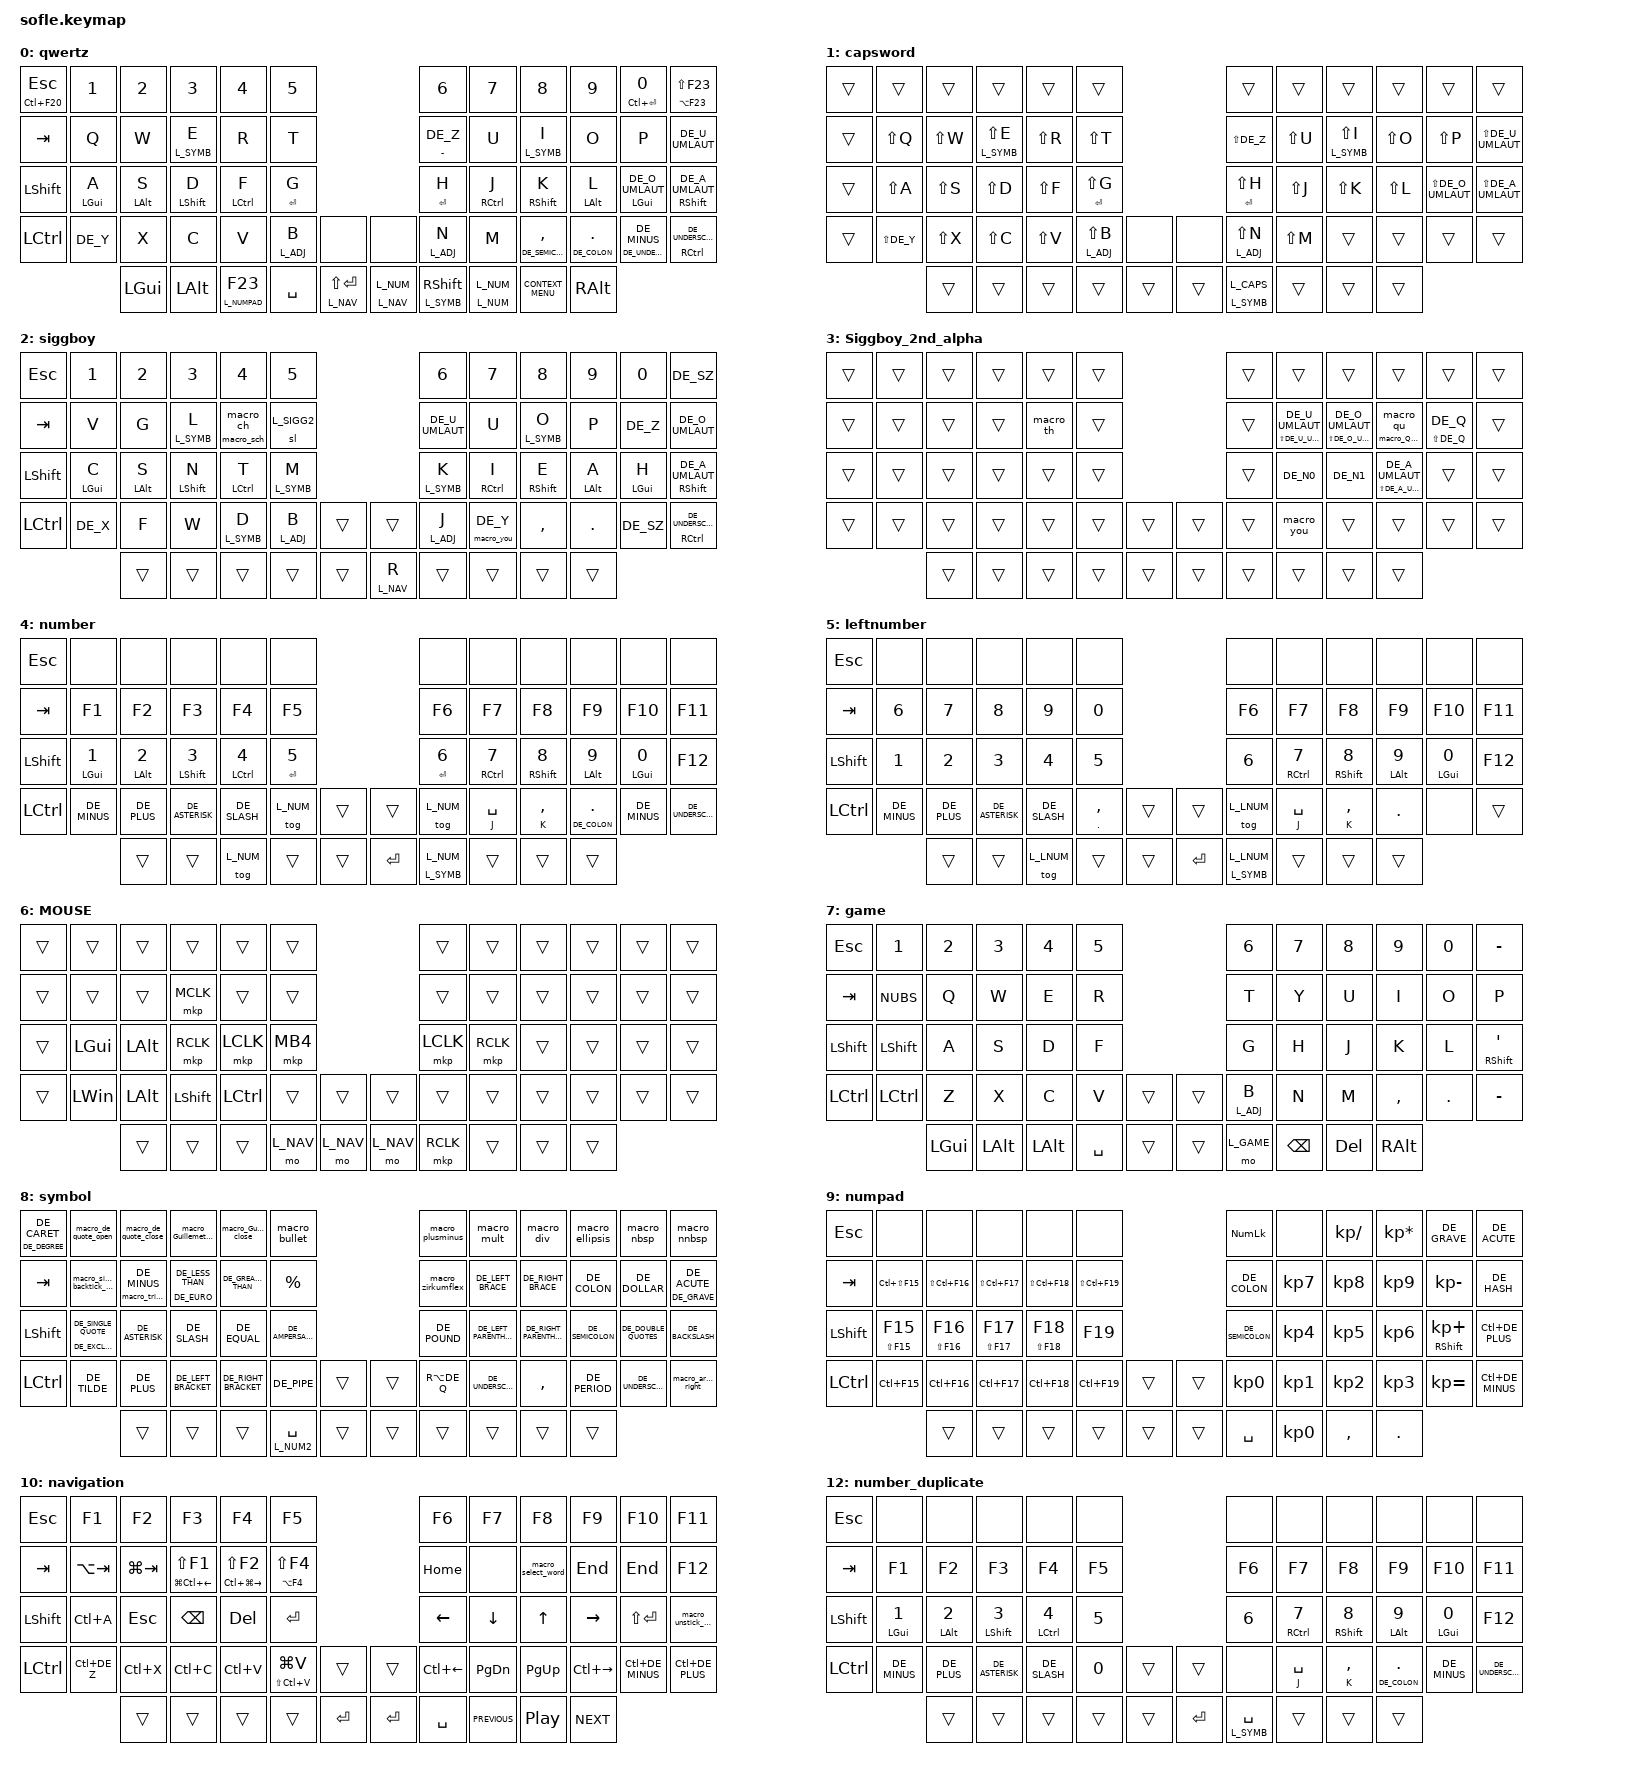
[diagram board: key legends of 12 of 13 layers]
/*
 * Copyright (c) 2020 The ZMK Contributors
 *
 * SPDX-License-Identifier: MIT
 */

#include <behaviors/anti_idle_mode.dtsi>
#include <dt-bindings/anti_idle_mode.h>
#include <behaviors.dtsi>
#include <dt-bindings/zmk/bt.h>
#include <dt-bindings/zmk/keys.h>
#include <dt-bindings/zmk/outputs.h>
#include <dt-bindings/zmk/pointing.h>

#ifndef KEYMAP_DRAWER

#include "keys_de.h"

#endif

// #include <behaviors/mouse.dtsi>
/* Global settings */

#define QUICK_TAP_MS 175

#include "layers.h"

&sl { ignore-modifiers; };

&left_encoder { steps = <60>; };

&right_encoder { steps = <60>; };

/ {
    // Activate ADJUST layer by pressing raise and lower

    conditional_layers { compatible = "zmk,conditional-layers"; };

    combos {
        compatible = "zmk,combos";

        combo_F24_minimize_Window {
            bindings = <&kp LC(F24)>;
            key-positions = <0 1>;
            layers = <LAYERS_MOST>;
            timeout-ms = <50>;
            require-prior-idle-ms = <90>;
        };

        combo_CTRL_Z {
            bindings = <&kp LC(DE_Z)>;
            key-positions = <>;
            layers = <LAYERS_MOST>;
            timeout-ms = <30>;
            require-prior-idle-ms = <100>;
        };

        combo_copy_cut {
            bindings = <&mt LC(X) LC(C)>;
            key-positions = <>;
            layers = <LAYERS_MOST>;
            timeout-ms = <30>;
            require-prior-idle-ms = <100>;
        };

        combo_CTRL_V {
            bindings = <&kp LC(V)>;
            key-positions = <>;
            layers = <LAYERS_MOST>;
            timeout-ms = <22>;
            require-prior-idle-ms = <100>;
        };

        combo_win_paste {
            bindings = <&mod_taptap_150 LS(LC(V)) LG(V)>;
            key-positions = <>;
            layers = <LAYERS_MOST>;
            timeout-ms = <30>;
            require-prior-idle-ms = <100>;
        };

        combo_CTRL_Y {
            bindings = <&kp LC(DE_Y)>;
            key-positions = <>;
            layers = <LAYERS_MOST>;
            timeout-ms = <30>;
            require-prior-idle-ms = <100>;
        };

        combo_CTRL_Backspace {
            bindings = <&kp LC(BACKSPACE)>;
            key-positions = <19 20>;
            layers = <LAYERS_MOST>;
            timeout-ms = <30>;
            require-prior-idle-ms = <100>;
        };

        combo_CTRL_Delete {
            bindings = <&kp LC(DELETE)>;
            key-positions = <20 21>;
            layers = <LAYERS_MOST>;
            timeout-ms = <25>;
            require-prior-idle-ms = <100>;
        };

        combo_Printscreen1 {
            bindings = <&kp PRINTSCREEN>;
            key-positions = <10 11>;
            layers = <LAYERS_MOST>;
            timeout-ms = <30>;
            require-prior-idle-ms = <100>;
        };

        combo_Guillemets_open {
            bindings = <&macro_Guillemets_open>;
            key-positions = <1 2>;
            layers = <LAYERS_WRITE>;
            timeout-ms = <40>;
            require-prior-idle-ms = <100>;
        };

        combo_Guillemets_close {
            bindings = <&macro_Guillemets_close>;
            key-positions = <2 3>;
            layers = <LAYERS_WRITE>;
            timeout-ms = <40>;
            require-prior-idle-ms = <100>;
        };

        combo_capsword {
            bindings = <&caps_word_al L_CAPS>;
            key-positions = <25 34>;
            layers = <LAYERS_WRITE>;
            timeout-ms = <65>;
            require-prior-idle-ms = <150>;
        };

        combo_en_dash2 {
            bindings = <&macro_en_dash>;
            key-positions = <48 47>;
            layers = <LAYERS_WRITE>;
            timeout-ms = <50>;
            require-prior-idle-ms = <100>;
        };

        combo_question {
            bindings = <&kp DE_QUESTION>;
            key-positions = <46 47>;
            layers = <LAYERS_MOST>;
            timeout-ms = <50>;
            require-prior-idle-ms = <75>;
        };

        combo_exclamation {
            bindings = <&kp EXCLAMATION>;
            key-positions = <46 45>;
            layers = <LAYERS_MOST>;
            timeout-ms = <45>;
            require-prior-idle-ms = <100>;
        };

        combo_Backspace {
            bindings = <&kp BACKSPACE>;
            key-positions = <31 32>;
            layers = <LAYERS_MOST>;
            timeout-ms = <30>;
            require-prior-idle-ms = <70>;
        };

        combo_listary_new {
            bindings = <&kp F22>;
            key-positions = <28 29>;
            layers = <LAYERS_MOST>;
            timeout-ms = <30>;
            require-prior-idle-ms = <100>;
        };

        combo_new_window {
            bindings = <&kp LC(N)>;
            key-positions = <16 17>;
            timeout-ms = <35>;
            require-prior-idle-ms = <300>;
            layers = <LAYERS_MOST>;
        };

        combo_em_dash2 {
            bindings = <&macro_em_dash>;
            key-positions = <47 48 46>;
            timeout-ms = <50>;
            require-prior-idle-ms = <100>;
            layers = <LAYERS_WRITE>;
        };

        combo_new_tab {
            bindings = <&kp LC(T)>;
            key-positions = <16 15>;
            timeout-ms = <30>;
            require-prior-idle-ms = <300>;
            layers = <LAYERS_MOST>;
        };

        combo_Delete {
            bindings = <&kp DELETE>;
            key-positions = <32 33>;
            timeout-ms = <25>;
            require-prior-idle-ms = <150>;
            layers = <LAYERS_MOST>;
        };

        combo_arrowa_right {
            bindings = <&macro_arrow_right>;
            key-positions = <48 49>;
            timeout-ms = <50>;
            require-prior-idle-ms = <100>;
            layers = <LAYERS_WRITE>;
        };

        combo_Paste_withouta_formatting {
            bindings = <&kp LC(LS(V))>;
            key-positions = <>;
            timeout-ms = <30>;
            require-prior-idle-ms = <100>;
            layers = <LAYERS_MOST>;
        };

        combo_change_audiodevice {
            bindings = <&kp LA(LS(LC(F14)))>;
            key-positions = <5 6>;
            timeout-ms = <40>;
            layers = <LAYERS_MOST>;
        };

        combo_Printscreen2 {
            bindings = <&kp PRINTSCREEN>;
            key-positions = <4 5>;
            timeout-ms = <40>;
            require-prior-idle-ms = <100>;
            layers = <LAYERS_MOST>;
        };

        combo_CTRL_Z_2 {
            bindings = <&kp LC(DE_Z)>;
            key-positions = <18 19>;
            timeout-ms = <30>;
            require-prior-idle-ms = <100>;
            layers = <LAYERS_MOST>;
        };

        combo_Menuekey {
            bindings = <&kp K_CONTEXT_MENU>;
            key-positions = <50 51>;
            timeout-ms = <30>;
            require-prior-idle-ms = <100>;
            layers = <LAYERS_MOST>;
        };

        combo_p {
            bindings = <&macro_p>;
            key-positions = <41 40>;
            layers = <L_ADJ>;
        };

        combo_escape {
            bindings = <&kp ESCAPE>;
            key-positions = <27 32>;
            timeout-ms = <55>;
            require-prior-idle-ms = <120>;
            layers = <LAYERS_ALL>;
        };

        combo_F24_minimize_Window_2 {
            bindings = <&kp LC(F24)>;
            key-positions = <15 14>;
            timeout-ms = <22>;
            require-prior-idle-ms = <150>;
            layers = <LAYERS_MOST>;
        };

        combo_number_layer_left {
            bindings = <&tog L_LNUM>;
            key-positions = <38 39>;
            layers = <LAYERS_WRITE>;
            timeout-ms = <50>;
            require-prior-idle-ms = <80>;
        };

        combo_exit_left_numberlayer {
            bindings = <&tog L_LNUM>;
            key-positions = <38 39>;
            layers = <L_LNUM>;
        };

        combo_escape2 {
            bindings = <&kp ESCAPE>;
            key-positions = <26 27>;
            timeout-ms = <30>;
            require-prior-idle-ms = <70>;
            layers = <LAYERS_ALL>;
        };

        combo_Shift_Enter {
            bindings = <&mod_taptap_150 LC(ENTER) LS(ENTER)>;
            key-positions = <31 30>;
            timeout-ms = <30>;
            require-prior-idle-ms = <70>;
            layers = <LAYERS_MOST>;
        };

        combo_raycast {
            bindings = <&kp LA(SPACE)>;
            key-positions = <28 27>;
            timeout-ms = <30>;
            require-prior-idle-ms = <70>;
            layers = <LAYERS_MOST>;
        };

        combo_f24_universal_key_2 {
            bindings = <&mod_taptap_150 LS(F24) F24>;
            key-positions = <28 31>;
            timeout-ms = <30>;
            require-prior-idle-ms = <70>;
            layers = <LAYERS_MOST>;
        };

        combo_+f24_universal_key_3 {
            bindings = <&kp LS(F24)>;
            key-positions = <28 30>;
            timeout-ms = <30>;
            require-prior-idle-ms = <70>;
            layers = <LAYERS_MOST>;
        };
    };

    macros {
        macro_Guillemets_open: macro_Guillemets_open {
            compatible = "zmk,behavior-macro";
            #binding-cells = <0>;
            bindings =
                <&macro_press>,
                <&kp LEFT_ALT>,
                <&macro_tap>,
                <&kp KP_N0 &kp KP_N1 &kp KP_N7 &kp KP_N1>,
                <&macro_release>,
                <&kp LEFT_ALT>;

            label = "MACRO_GUILLEMETS_OPEN";
            wait-ms = <7>;
            tap-ms = <10>;
        };

        macro_Guillemets_close: macro_Guillemets_close {
            compatible = "zmk,behavior-macro";
            #binding-cells = <0>;
            bindings =
                <&macro_press>,
                <&kp LEFT_ALT>,
                <&macro_tap>,
                <&kp KP_N0 &kp KP_N1 &kp KP_N8 &kp KP_N7>,
                <&macro_release>,
                <&kp LEFT_ALT>;

            label = "MACRO_GUILLEMETS_CLOSE";
            wait-ms = <7>;
            tap-ms = <10>;
        };

        // 1: Deutsch Anführungszeichen unten „ (Alt+0132)

        macro_de_quote_open: macro_de_quote_open {
            compatible = "zmk,behavior-macro";
            #binding-cells = <0>;
            wait-ms = <7>;
            tap-ms = <10>;
            bindings =
                <&macro_press>,
                <&kp LALT>,
                <&macro_tap>,
                <&kp KP_N0 &kp KP_N1 &kp KP_N3 &kp KP_N2>,
                <&macro_release>,
                <&kp LALT>;
        };

        // 2: Deutsch Anführungszeichen oben “ (Alt+0147)

        macro_de_quote_close: macro_de_quote_close {
            compatible = "zmk,behavior-macro";
            #binding-cells = <0>;
            wait-ms = <7>;
            tap-ms = <10>;
            bindings =
                <&macro_press>,
                <&kp LALT>,
                <&macro_tap>,
                <&kp KP_N0 &kp KP_N1 &kp KP_N4 &kp KP_N7>,
                <&macro_release>,
                <&kp LALT>;
        };

        // 3: Französische Guillemets open « (Alt+0171)
        // 4: Französische Guillemets close » (Alt+0187)
        // 5: Bullet Point • (Alt+0149)

        macro_bullet: macro_bullet {
            compatible = "zmk,behavior-macro";
            #binding-cells = <0>;
            wait-ms = <7>;
            tap-ms = <10>;
            bindings =
                <&macro_press>,
                <&kp LALT>,
                <&macro_tap>,
                <&kp KP_N0 &kp KP_N1 &kp KP_N4 &kp KP_N9>,
                <&macro_release>,
                <&kp LALT>;
        };

        // 6: Ellipse … (Alt+0133)

        macro_ellipsis: macro_ellipsis {
            compatible = "zmk,behavior-macro";
            #binding-cells = <0>;
            wait-ms = <7>;
            tap-ms = <10>;
            bindings =
                <&macro_press>,
                <&kp LALT>,
                <&macro_tap>,
                <&kp KP_N0 &kp KP_N1 &kp KP_N3 &kp KP_N3>,
                <&macro_release>,
                <&kp LALT>;
        };

        // 7: Plus-Minus ± (Alt+0177)

        macro_plusminus: macro_plusminus {
            compatible = "zmk,behavior-macro";
            #binding-cells = <0>;
            wait-ms = <7>;
            tap-ms = <10>;
            bindings =
                <&macro_press>,
                <&kp LALT>,
                <&macro_tap>,
                <&kp KP_N0 &kp KP_N1 &kp KP_N7 &kp KP_N7>,
                <&macro_release>,
                <&kp LALT>;
        };

        // 8: Ungefähr ≈ (Alt+247)

        macro_approx: macro_approx {
            compatible = "zmk,behavior-macro";
            #binding-cells = <0>;
            wait-ms = <7>;
            tap-ms = <10>;
            bindings =
                <&macro_press>,
                <&kp LALT>,
                <&macro_tap>,
                <&kp KP_N2 &kp KP_N4 &kp KP_N7>,
                <&macro_release>,
                <&kp LALT>;
        };

        // ’ Typografischer Apostroph (Alt+0146)

        macro_apostrophe: macro_apostrophe {
            compatible = "zmk,behavior-macro";
            #binding-cells = <0>;
            wait-ms = <7>;
            tap-ms = <10>;
            bindings =
                <&macro_press>,
                <&kp LALT>,
                <&macro_tap>,
                <&kp KP_N0 &kp KP_N1 &kp KP_N4 &kp KP_N6>,
                <&macro_release>,
                <&kp LALT>;
        };

        // × Echtes Mal-Zeichen (Alt+0215)

        macro_mult: macro_mult {
            compatible = "zmk,behavior-macro";
            #binding-cells = <0>;
            wait-ms = <7>;
            tap-ms = <10>;
            bindings =
                <&macro_press>,
                <&kp LALT>,
                <&macro_tap>,
                <&kp KP_N0 &kp KP_N2 &kp KP_N1 &kp KP_N5>,
                <&macro_release>,
                <&kp LALT>;
        };

        // ÷ Geteilt-Zeichen (Alt+0247)

        macro_div: macro_div {
            compatible = "zmk,behavior-macro";
            #binding-cells = <0>;
            wait-ms = <7>;
            tap-ms = <10>;
            bindings =
                <&macro_press>,
                <&kp LALT>,
                <&macro_tap>,
                <&kp KP_N0 &kp KP_N2 &kp KP_N4 &kp KP_N7>,
                <&macro_release>,
                <&kp LALT>;
        };

        // NBSP: Geschütztes Leerzeichen (Alt+0160)

        macro_nbsp: macro_nbsp {
            compatible = "zmk,behavior-macro";
            #binding-cells = <0>;
            wait-ms = <7>;
            tap-ms = <10>;
            bindings =
                <&macro_press>,
                <&kp LALT>,
                <&macro_tap>,
                <&kp KP_N0 &kp KP_N1 &kp KP_N6 &kp KP_N0>,
                <&macro_release>,
                <&kp LALT>;
        };

        // NNBSP: Schmales geschütztes Leerzeichen (Alt+8239)
        // Hinweis: Windows unterstützt vierstellige Alt-Codes über 255 oft nur 
        // mit dem "EnableHexNumpad" Registry-Key. Dies ist der "Best Effort" Code:

        macro_nnbsp: macro_nnbsp {
            compatible = "zmk,behavior-macro";
            #binding-cells = <0>;
            wait-ms = <7>;
            tap-ms = <10>;
            bindings =
                <&macro_press>,
                <&kp LALT>,
                <&macro_tap>,
                <&kp KP_N8 &kp KP_N2 &kp KP_N3 &kp KP_N9>,
                <&macro_release>,
                <&kp LALT>;
        };

        macro_select_word: select_word {
            compatible = "zmk,behavior-macro";
            #binding-cells = <0>;
            bindings =
                <&macro_press>,
                <&kp LCTRL>,
                <&macro_tap>,
                <&kp LEFT_ARROW &kp LS(RIGHT_ARROW)>,
                <&macro_release>,
                <&kp LEFT_CONTROL>;

            label = "SELECT_WORD";
            wait-ms = <7>;
            tap-ms = <10>;
        };

        macro_en_dash: macro_en_dash {
            compatible = "zmk,behavior-macro";
            #binding-cells = <0>;
            bindings =
                <&macro_press>,
                <&kp LEFT_ALT>,
                <&macro_tap>,
                <&kp KP_NUMBER_0 &kp KP_NUMBER_1 &kp KP_NUMBER_5 &kp KP_NUMBER_0>,
                <&macro_release>,
                <&kp LEFT_ALT>;

            label = "MACRO_EN_DASH";
        };

        macro_em_dash: macro_em_dash {
            compatible = "zmk,behavior-macro";
            #binding-cells = <0>;
            bindings =
                <&macro_press>,
                <&kp LEFT_ALT>,
                <&macro_tap>,
                <&kp KP_NUMBER_0 &kp KP_NUMBER_1 &kp KP_NUMBER_5 &kp KP_NUMBER_1>,
                <&macro_release>,
                <&kp LEFT_ALT>;

            label = "MACRO_EM_DASH";
        };

        macro_arrow_right: macro_arrow_right {
            compatible = "zmk,behavior-macro";
            #binding-cells = <0>;
            bindings =
                <&macro_press>,
                <&kp LEFT_ALT>,
                <&macro_tap>,
                <&kp KP_NUMBER_2 &kp KP_NUMBER_6>,
                <&macro_release>,
                <&kp LEFT_ALT>;

            label = "MACRO_ARROW_RIGHT";
        };

        macro_single_backtick_grave: macro_single_backtick {
            compatible = "zmk,behavior-macro";
            #binding-cells = <0>;
            bindings = <&macro_tap>, <&kp LS(EQUAL) &kp SPACE>;

            label = "MACRO_SINGLE_BACKTICK";
        };

        macro_triple_backtick: macro_tripple_backtick {
            compatible = "zmk,behavior-macro";
            #binding-cells = <0>;
            bindings =
                <&macro_tap>,
                <&kp LS(EQUAL) &kp SPACE &kp LS(EQUAL) &kp SPACE &kp LS(EQUAL) &kp SPACE>;

            label = "MACRO_TRIPPLE_BACKTICK";
            wait-ms = <6>;
            tap-ms = <9>;
        };

        macro_zirkumflex: macro_zirkumflex {
            compatible = "zmk,behavior-macro";
            #binding-cells = <0>;
            bindings = <&macro_tap>, <&kp GRAVE &kp SPACE>;

            label = "MACRO_ZIRKUMFLEX";
        };

        macro_p: macro_p {
            compatible = "zmk,behavior-macro";
            #binding-cells = <0>;
            wait-ms = <6>;
            tap-ms = <8>;
            bindings = <&kp LS(L) &kp A &kp L &kp E &kp F &kp A &kp R &kp N &kp DE_PLUS &kp S &kp D &kp F &kp S &kp D &kp F>;
            label = "MACRO_P";
        };

        macro_ch: macro_thorn_key {
            compatible = "zmk,behavior-macro";
            #binding-cells = <0>;
            wait-ms = <7>;
            tap-ms = <10>;
            bindings = <&kp C &kp H>;
            label = "MACRO_THORN_KEY";
        };

        macro_sch: macro_thorn_key_held {
            compatible = "zmk,behavior-macro";
            #binding-cells = <0>;
            wait-ms = <7>;
            tap-ms = <10>;
            bindings = <&kp S &kp C &kp H>;
            label = "MACRO_THORN_KEY_HELD";
        };

        macro_and: macro_and {
            compatible = "zmk,behavior-macro";
            #binding-cells = <0>;
            bindings = <&kp A &kp N &kp D>;
            label = "MACRO_AND";
            wait-ms = <5>;
            tap-ms = <8>;
        };

        macro_you: macro_you {
            compatible = "zmk,behavior-macro";
            #binding-cells = <0>;
            bindings = <&kp DE_Y &kp O &kp U>;
            label = "MACRO_YOU";
            wait-ms = <5>;
            tap-ms = <8>;
        };

        macro_email: macro_email {
            compatible = "zmk,behavior-macro";
            #binding-cells = <0>;
            bindings = <&kp J &kp O &kp H &kp A &kp N &kp N &kp E &kp S &kp DE_AT &kp B &kp U &kp L &kp D &kp M &kp A &kp N &kp N &kp DOT &kp D &kp E>;
            label = "MACRO_EMAIL";
            wait-ms = <5>;
            tap-ms = <8>;
        };

        macro_th: macro_th {
            compatible = "zmk,behavior-macro";
            #binding-cells = <0>;
            wait-ms = <7>;
            tap-ms = <10>;
            bindings = <&kp T &kp H>;
            label = "MACRO_TH";
        };

        macro_qu: macro_qu {
            compatible = "zmk,behavior-macro";
            #binding-cells = <0>;
            wait-ms = <7>;
            tap-ms = <10>;
            bindings = <&kp Q &kp U>;
            label = "MACRO_QU";
        };

        macro_Qu_capitalized: macro_Qu_capitalized {
            compatible = "zmk,behavior-macro";
            #binding-cells = <0>;
            wait-ms = <7>;
            tap-ms = <10>;
            bindings = <&kp LS(Q) &kp U>;
            label = "MACRO_QU_CAPITALIZED";
        };

        macro_unstick_mods: macro_unstick_mods {
            label = "MACRO_UNSTICK_MODS";
            compatible = "zmk,behavior-macro";
            #binding-cells = <0>;
            wait-ms = <16>;
            tap-ms = <20>;
            bindings = <&kp LSHIFT &kp RSHIFT &kp LCTRL &kp RCTRL &kp LALT &kp RALT &kp LGUI &kp RGUI>;
        };

        anti_idle {
            compatible = "zmk,anti-idle-generic";
            interval-ms = <15000>;                      // Alle 60 Sekunden aktiv werden
            bindings = <&mmv MOVE_DOWN &mmv MOVE_UP>;   // Schiebt die Maus kurz runter und hoch
            tap_ms = <100>;                              // Sehr kurze Bewegung, damit es nicht nervt
            wait_ms = <200>;                             // Pause zwischen Runter und Hoch
        };
    };

    behaviors {
        hrm_shift_l: hrm_shift_l {
            compatible = "zmk,behavior-hold-tap";
            label = "HRM_SHIFT_L";
            bindings = <&kp>, <&kp>;

            #binding-cells = <2>;
            tapping-term-ms = <300>;
            quick-tap-ms = <175>;
            flavor = "balanced";
            hold-trigger-key-positions = <18 19 6 7 8 9 10 11 23 22 21 20 30 31 32 33 34 35 45 44 46 47 48 49 59 58 57 56 55>;
            require-prior-idle-ms = <60>;
            hold-trigger-on-release;
        };

        hrm_shift_r: hrm_shift_r {
            compatible = "zmk,behavior-hold-tap";
            label = "HRM_SHIFT_R";
            bindings = <&kp>, <&kp>;

            #binding-cells = <2>;
            tapping-term-ms = <300>;
            quick-tap-ms = <230>;
            flavor = "balanced";
            hold-trigger-key-positions = <54 53 52 51 50 36 37 38 39 40 41 29 4 5 16 28 27 15 3 2 14 26 25 24 12 13 0 1 17>;
            require-prior-idle-ms = <60>;
            hold-trigger-on-release;
        };

        mod_taptap_150: mod_taptap_150 {
            compatible = "zmk,behavior-hold-tap";
            label = "MOD_TAPTAP_150";
            bindings = <&kp>, <&kp>;

            #binding-cells = <2>;
            flavor = "tap-preferred";
            tapping-term-ms = <150>;
        };

        hrm_momentary_layer_l: hrm_momentary_layer_l {
            compatible = "zmk,behavior-hold-tap";
            label = "HRM_MOMENTARY_LAYER_L";
            bindings = <&mo>, <&kp>;

            #binding-cells = <2>;
            tapping-term-ms = <200>;
            quick-tap-ms = <175>;
            flavor = "balanced";
            hold-trigger-key-positions = <18 19 6 7 8 9 10 11 23 22 21 20 30 31 32 33 34 35 45 44 46 47 48 49 59 58 57 56 55>;
            require-prior-idle-ms = <80>;
        };

        hrm_momentary_layer: hrm_momentary_layer {
            compatible = "zmk,behavior-hold-tap";
            label = "HRM_MOMENTARY_LAYER";
            bindings = <&mo>, <&kp>;

            #binding-cells = <2>;
            tapping-term-ms = <280>;
            quick-tap-ms = <175>;
            flavor = "balanced";
            require-prior-idle-ms = <100>;
        };

        mod_tapBackticSingle: mod_tapBackticSingle {
            compatible = "zmk,behavior-hold-tap";
            label = "MOD_TAPBACKTICSINGLE";
            bindings = <&macro_single_backtick_grave>, <&kp>;

            #binding-cells = <2>;
            flavor = "tap-preferred";
            tapping-term-ms = <155>;
        };

        mod_tapBackticTrippe: mod_tapBackticTrippe {
            compatible = "zmk,behavior-hold-tap";
            label = "MOD_TAPBACKTICTRIPPE";
            bindings = <&macro_triple_backtick>, <&kp>;

            #binding-cells = <2>;
            flavor = "tap-preferred";
            tapping-term-ms = <155>;
        };

        hrm_mods_left: hrm_mods_left {
            compatible = "zmk,behavior-hold-tap";
            label = "HRM_MODS_LEFT";
            bindings = <&kp>, <&kp>;

            #binding-cells = <2>;
            tapping-term-ms = <300>;
            quick-tap-ms = <175>;
            flavor = "balanced";
            hold-trigger-key-positions = <18 19 6 7 8 9 10 11 23 22 21 20 30 31 32 33 34 35 45 44 46 47 48 49 59 58 57 56 55>;
            require-prior-idle-ms = <150>;
            hold-trigger-on-release;
        };

        hrm_mods_right: hrm_mods_right {
            compatible = "zmk,behavior-hold-tap";
            label = "HRM_MODS_RIGHT";
            bindings = <&kp>, <&kp>;

            #binding-cells = <2>;
            tapping-term-ms = <300>;
            quick-tap-ms = <280>;
            flavor = "balanced";
            hold-trigger-key-positions = <54 53 52 51 50 36 37 38 39 40 41 29 4 5 16 28 27 15 3 2 14 26 25 24 12 13 0 1 17>;
            require-prior-idle-ms = <150>;
            hold-trigger-on-release;
        };

        sticky_shift: sticky_shift {
            compatible = "zmk,behavior-sticky-key";
            label = "STICKY_SHIFT";
            bindings = <&kp>;
            #binding-cells = <1>;
            release-after-ms = <1000>;
            quick-release;
            ignore-modifiers;
            lazy;
        };

        mod_thorn_key: mod_thorn_key {
            compatible = "zmk,behavior-hold-tap";
            label = "MOD_THORN_KEY";
            bindings = <&macro_sch>, <&macro_ch>;

            #binding-cells = <2>;
            flavor = "tap-preferred";
            tapping-term-ms = <165>;
        };

        mod_d_and: mod_d_and {
            compatible = "zmk,behavior-hold-tap";
            label = "MOD_D_AND";
            bindings = <&macro_and>, <&kp>;

            #binding-cells = <2>;
            flavor = "tap-preferred";
            tapping-term-ms = <160>;
        };

        mod_y_you: mod_y_you {
            compatible = "zmk,behavior-hold-tap";
            label = "MOD_Y_YOU";
            bindings = <&macro_you>, <&kp>;

            #binding-cells = <2>;
            flavor = "tap-preferred";
            tapping-term-ms = <160>;
        };

        // Hold: Momentary Layer | Tap: Num Word

        smart_num: smart_num {
            compatible = "zmk,behavior-hold-tap";
            #binding-cells = <2>;
            flavor = "hold-preferred";
            tapping-term-ms = <200>;
            quick-tap-ms = <175>;
            bindings = <&mo>, <&num_word>;
        };

        num_word: num_word {
            compatible = "zmk,behavior-auto-layer";
            #binding-cells = <1>;
            continue-list = <
                N1 N2 N3 N4 N5 N6 N7 N8 N9 N0
                DE_DOT DE_COMMA DE_PLUS DE_MINUS DE_ASTRK DE_SLASH DE_EQUAL
                DE_UNDERSCORE BSPC DEL
            >;

            ignore-modifiers;
        };

        // Caps Word als Auto-Layer: Exit per Tap auf die One-Shot-Shift-Position

        caps_word_al: caps_word_al {
            compatible = "zmk,behavior-auto-layer";
            #binding-cells = <1>;
            continue-list = <
                A B C D E F G H I J K L M N O P Q R S T U V W X Y Z
                DE_A_UMLAUT DE_O_UMLAUT DE_U_UMLAUT DE_SZ
                N1 N2 N3 N4 N5 N6 N7 N8 N9 N0
                DE_MINUS DE_UNDERSCORE BSPC DEL
            >;

            ignore-modifiers;
        };

        // Hold: Momentary Layer | Tap: Caps Word beenden

        momentary_layer_caps_exit: momentary_layer_caps_exit {
            compatible = "zmk,behavior-hold-tap";
            label = "MOMENTARY_LAYER_CAPS_EXIT";
            bindings = <&mo>, <&caps_word_al>;

            #binding-cells = <2>;
            tapping-term-ms = <280>;
            flavor = "balanced";
            quick-tap-ms = <333>;
        };

        momentary_layer_sticky_shif: momentary_layer_sticky_shif {
            compatible = "zmk,behavior-hold-tap";
            label = "MOMENTARY_LAYER_STICKY_SHIF";
            bindings = <&mo>, <&sticky_shift>;

            #binding-cells = <2>;
            tapping-term-ms = <280>;
            flavor = "balanced";
            quick-tap-ms = <333>;
        };

        hrm_momentary_layer_r: hrm_momentary_layer_r {
            compatible = "zmk,behavior-hold-tap";
            label = "HRM_MOMENTARY_LAYER_R";
            bindings = <&mo>, <&kp>;

            #binding-cells = <2>;
            tapping-term-ms = <200>;
            quick-tap-ms = <175>;
            flavor = "balanced";
            require-prior-idle-ms = <80>;
            hold-trigger-key-positions = <0 1 12 13 14 15 16 17 24 25 26 27 28 29 36 37 38 39 40 41 42 50 51 52 53 54 2 3 4 5>;
        };

        layer_tap_prior_idle: layer_tap_prior_idle {
            compatible = "zmk,behavior-hold-tap";
            label = "LAYER_TAP_PRIOR_IDLE";
            bindings = <&mo>, <&kp>;

            #binding-cells = <2>;
            tapping-term-ms = <200>;
            quick-tap-ms = <333>;
            require-prior-idle-ms = <120>;
            flavor = "balanced";
        };

        hrm_mods_left_short_tappingterm: hrm_mods_left_short_tappingterm {
            compatible = "zmk,behavior-hold-tap";
            label = "HRM_MODS_LEFT_SHORT_TAPPINGTERM";
            bindings = <&kp>, <&kp>;

            #binding-cells = <2>;
            tapping-term-ms = <180>;
            quick-tap-ms = <175>;
            flavor = "balanced";
            hold-trigger-key-positions = <18 19 6 7 8 9 10 11 23 22 21 20 30 31 32 33 34 35 45 44 46 47 48 49 59 58 57 56 55>;
            require-prior-idle-ms = <150>;
            hold-trigger-on-release;
        };

        mod_qu_Qu: mod_qu_Qu {
            compatible = "zmk,behavior-hold-tap";
            label = "MOD_QU_QU";
            #binding-cells = <2>;
            flavor = "tap-preferred";
            tapping-term-ms = <150>;
            bindings = <&macro_Qu_capitalized>, <&macro_qu>;
        };

        momentary_layer_adjust: momentary_layer_adjust {
            compatible = "zmk,behavior-hold-tap";
            label = "MOMENTARY_LAYER_ADJUST";
            bindings = <&mo>, <&kp>;

            #binding-cells = <2>;
            tapping-term-ms = <400>;
            flavor = "tap-preferred";
            require-prior-idle-ms = <150>;
        };

        momentary_layer_oneshot_layer: momentary_layer_oneshot_layer {
            compatible = "zmk,behavior-hold-tap";
            label = "MOMENTARY_LAYER_ONESHOT_LAYER";
            bindings = <&mo>, <&sl>;

            #binding-cells = <2>;
            tapping-term-ms = <280>;
            flavor = "balanced";
            quick-tap-ms = <333>;
        };

        mod_taaap: mod_taaap {
            compatible = "zmk,behavior-hold-tap";
            label = "MOD_TAAAP";
            bindings = <&kp>, <&kp>;

            #binding-cells = <2>;
            flavor = "tap-preferred";
            tapping-term-ms = <200>;
        };

        layer_repeat: layer_repeat {
            compatible = "zmk,behavior-hold-tap";
            label = "LAYER_REPEAT";
            bindings = <&mo>, <&key_repeat>;

            #binding-cells = <2>;
            flavor = "balanced";
            tapping-term-ms = <160>;
        };

        MOMENTARY_LAYER_TOGGLE: MOMENTARY_LAYER_TOGGLE {
            compatible = "zmk,behavior-hold-tap";
            label = "MOMENTARY_LAYER_TOGGLE";
            bindings = <&mo>, <&tog>;

            #binding-cells = <2>;
            tapping-term-ms = <280>;
            quick-tap-ms = <175>;
            flavor = "balanced";
            require-prior-idle-ms = <100>;
        };
    };

    sensors: sensors {
        compatible = "zmk,keymap-sensors";
        sensors = <&left_encoder &right_encoder>;
        triggers-per-rotation = <30>;
    };

    keymap {
        compatible = "zmk,keymap";

        QWERTZ_Layer {
            display-name = "qwertz";
            bindings = <
&mod_taaap LC(F20) ESC  &kp N1                                       &kp N2                     &kp N3                           &kp N4                         &kp N5                                                                          &kp N6                                           &kp N7                           &kp N8                              &kp N9                        &mod_taptap_150 LC(ENTER) N0            &mod_taptap_150 LA(F23) LS(F23)
&kp TAB                 &kp Q                                        &kp W                      &hrm_momentary_layer_l L_SYMB E  &kp R                          &kp T                                                                           &mod_taptap_150 MINUS DE_Z                       &kp U                            &hrm_momentary_layer_r L_SYMB I     &kp O                         &kp P                                   &kp DE_U_UMLAUT
&kp LEFT_SHIFT          &hrm_mods_left_short_tappingterm LEFT_GUI A  &hrm_mods_left LEFT_ALT S  &hrm_shift_l LEFT_SHIFT D        &hrm_mods_left LEFT_CONTROL F  &mod_taaap ENTER G                                                              &mod_taaap ENTER H                               &hrm_mods_right RIGHT_CONTROL J  &hrm_shift_r RIGHT_SHIFT K          &hrm_mods_right LEFT_ALT L    &hrm_mods_right LEFT_GUI DE_O_UMLAUT    &hrm_shift_r RIGHT_SHIFT DE_A_UMLAUT
&kp LCTRL               &kp DE_Y                                     &kp X                      &kp C                            &kp V                          &momentary_layer_adjust L_ADJ B  &none                  &none                   &momentary_layer_adjust L_ADJ N                  &kp M                            &mod_taptap_150 DE_SEMICOLON COMMA  &mod_taptap_150 DE_COLON DOT  &mod_taptap_150 DE_UNDERSCORE DE_MINUS  &hrm_shift_r RIGHT_CONTROL DE_UNDERSCORE
                                                                     &kp LGUI                   &kp LALT                         &lt L_NUMPAD F23               &kp SPACE                        &lt L_NAV LS(ENTER)    &smart_num L_NAV L_NUM  &momentary_layer_sticky_shif L_SYMB RIGHT_SHIFT  &smart_num L_NUM L_NUM           &kp K_CONTEXT_MENU                  &kp RALT
            >;

            sensor-bindings = <&inc_dec_kp C_VOL_UP C_VOL_DN>;
        };

        capsword_layer {
            display-name = "capsword";
            bindings = <
&trans  &trans        &trans     &trans                               &trans     &trans                                                 &trans                                    &trans     &trans                               &trans     &trans               &trans
&trans  &kp LS(Q)     &kp LS(W)  &hrm_momentary_layer_l L_SYMB LS(E)  &kp LS(R)  &kp LS(T)                                              &kp LS(DE_Z)                              &kp LS(U)  &hrm_momentary_layer_r L_SYMB LS(I)  &kp LS(O)  &kp LS(P)            &kp LS(DE_U_UMLAUT)
&trans  &kp LS(A)     &kp LS(S)  &kp LS(D)                            &kp LS(F)  &mod_taaap ENTER LS(G)                                 &mod_taaap ENTER LS(H)                    &kp LS(J)  &kp LS(K)                            &kp LS(L)  &kp LS(DE_O_UMLAUT)  &kp LS(DE_A_UMLAUT)
&trans  &kp LS(DE_Y)  &kp LS(X)  &kp LS(C)                            &kp LS(V)  &momentary_layer_adjust L_ADJ LS(B)  &none     &none   &momentary_layer_adjust L_ADJ LS(N)       &kp LS(M)  &trans                               &trans     &trans               &trans
                      &trans     &trans                               &trans     &trans                               &trans    &trans  &momentary_layer_caps_exit L_SYMB L_CAPS  &trans     &trans                               &trans
            >;

            sensor-bindings = <&inc_dec_kp C_VOL_UP C_VOL_DN>;
        };

        Siggboy_Layer {
            display-name = "siggboy";
            bindings = <
&kp ESC         &kp N1                                       &kp N2                     &kp N3                           &kp N4                           &kp N5                                                  &kp N6                           &kp N7                           &kp N8                           &kp N9                      &kp N0                      &kp DE_SZ
&kp TAB         &kp V                                        &kp G                      &hrm_momentary_layer_l L_SYMB L  &mod_thorn_key 0 0               &sl L_SIGG2                                             &kp DE_U_UMLAUT                  &kp U                            &hrm_momentary_layer_r L_SYMB O  &kp P                       &kp DE_Z                    &kp DE_O_UMLAUT
&kp LEFT_SHIFT  &hrm_mods_left_short_tappingterm LEFT_GUI C  &hrm_mods_left LEFT_ALT S  &hrm_shift_l LEFT_SHIFT N        &hrm_mods_left LEFT_CONTROL T    &hrm_momentary_layer_l L_SYMB M                         &hrm_momentary_layer_r L_SYMB K  &hrm_mods_right RIGHT_CONTROL I  &hrm_shift_r RIGHT_SHIFT E       &hrm_mods_right LEFT_ALT A  &hrm_mods_right LEFT_GUI H  &hrm_shift_r RIGHT_SHIFT DE_A_UMLAUT
&kp LCTRL       &kp DE_X                                     &kp F                      &kp W                            &hrm_momentary_layer_l L_SYMB D  &hrm_momentary_layer L_ADJ B     &trans    &trans       &hrm_momentary_layer L_ADJ J     &mod_y_you 0 DE_Y                &kp COMMA                        &kp DOT                     &kp DE_SZ                   &hrm_shift_r RIGHT_CONTROL DE_UNDERSCORE
                                                             &trans                     &trans                           &trans                           &trans                           &trans    &lt L_NAV R  &trans                           &trans                           &trans                           &trans
            >;

            sensor-bindings = <&inc_dec_kp C_VOL_UP C_VOL_DN>;
        };

        Siggboy_2nd_alpha {
            bindings = <
&trans  &trans  &trans  &trans  &trans     &trans                    &trans  &trans                                       &trans                                       &trans                                       &trans                         &trans
&trans  &trans  &trans  &trans  &macro_th  &trans                    &trans  &mod_taptap_150 LS(DE_U_UMLAUT) DE_U_UMLAUT  &mod_taptap_150 LS(DE_O_UMLAUT) DE_O_UMLAUT  &mod_qu_Qu 0 0                               &mod_taptap_150 LS(DE_Q) DE_Q  &trans
&trans  &trans  &trans  &trans  &trans     &trans                    &trans  &kp DE_N0                                    &kp DE_N1                                    &mod_taptap_150 LS(DE_A_UMLAUT) DE_A_UMLAUT  &trans                         &trans
&trans  &trans  &trans  &trans  &trans     &trans  &trans    &trans  &trans  &macro_you                                   &trans                                       &trans                                       &trans                         &trans
                &trans  &trans  &trans     &trans  &trans    &trans  &trans  &trans                                       &trans                                       &trans
            >;
        };

        Number_layer {
            display-name = "number";
            bindings = <
&kp ESCAPE        &none                                         &none                       &none                         &none                           &none                                     &none                                 &none                             &none                           &none                         &none                        &none
&kp TAB           &kp F1                                        &kp F2                      &kp F3                        &kp F4                          &kp F5                                    &kp F6                                &kp F7                            &kp F8                          &kp F9                        &kp F10                      &kp F11
&kp LSHFT         &hrm_mods_left_short_tappingterm LEFT_GUI N1  &hrm_mods_left LEFT_ALT N2  &hrm_mods_left LEFT_SHIFT N3  &hrm_mods_left LEFT_CONTROL N4  &mod_taaap ENTER N5                       &mod_taaap ENTER N6                   &hrm_mods_right RIGHT_CONTROL N7  &hrm_mods_right RIGHT_SHIFT N8  &hrm_mods_right LALT N9       &hrm_mods_right LEFT_GUI N0  &kp F12
&kp LEFT_CONTROL  &kp DE_MINUS                                  &kp DE_PLUS                 &kp DE_ASTERISK               &kp DE_SLASH                    &tog L_NUM           &trans    &trans     &tog L_NUM                            &mod_taptap_150 J SPACE           &mod_taptap_150 K COMMA         &mod_taptap_150 DE_COLON DOT  &kp DE_MINUS                 &kp DE_UNDERSCORE
                                                                &trans                      &trans                        &tog L_NUM                      &trans               &trans    &kp ENTER  &MOMENTARY_LAYER_TOGGLE L_SYMB L_NUM  &trans                            &trans                          &trans
            >;

            sensor-bindings =
                <&inc_dec_kp C_VOL_UP C_VOL_DN>,
                <&inc_dec_kp K_SCROLL_UP K_SCROLL_DOWN>;
        };

        lefthand_number_layer {
            display-name = "leftnumber";
            bindings = <
&kp ESCAPE        &none         &none        &none            &none         &none                                           &none                                  &none                             &none                           &none                    &none                        &none
&kp TAB           &kp N6        &kp N7       &kp N8           &kp N9        &kp N0                                          &kp F6                                 &kp F7                            &kp F8                          &kp F9                   &kp F10                      &kp F11
&kp LSHFT         &kp N1        &kp N2       &kp N3           &kp N4        &kp N5                                          &kp N6                                 &hrm_mods_right RIGHT_CONTROL N7  &hrm_mods_right RIGHT_SHIFT N8  &hrm_mods_right LALT N9  &hrm_mods_right LEFT_GUI N0  &kp F12
&kp LEFT_CONTROL  &kp DE_MINUS  &kp DE_PLUS  &kp DE_ASTERISK  &kp DE_SLASH  &mod_taptap_150 DOT COMMA  &trans    &trans     &tog L_LNUM                            &mod_taptap_150 J SPACE           &mod_taptap_150 K COMMA         &kp DOT                  &none                        &trans
                                &trans       &trans           &tog L_LNUM   &trans                     &trans    &kp ENTER  &MOMENTARY_LAYER_TOGGLE L_SYMB L_LNUM  &trans                            &trans                          &trans
            >;

            sensor-bindings = <&inc_dec_kp C_VOL_UP C_VOL_DN>;
        };

        MOUSE {
            bindings = <
&trans  &trans        &trans        &trans          &trans            &trans                             &trans     &trans     &trans  &trans  &trans  &trans
&trans  &trans        &trans        &mkp MCLK       &trans            &trans                             &trans     &trans     &trans  &trans  &trans  &trans
&trans  &kp LEFT_GUI  &kp LEFT_ALT  &mkp RCLK       &mkp LCLK         &mkp MB4                           &mkp LCLK  &mkp RCLK  &trans  &trans  &trans  &trans
&trans  &kp LEFT_WIN  &kp LEFT_ALT  &kp LEFT_SHIFT  &kp LEFT_CONTROL  &trans     &trans       &trans     &trans     &trans     &trans  &trans  &trans  &trans
                      &trans        &trans          &trans            &mo L_NAV  &mo L_NAV    &mo L_NAV  &mkp RCLK  &trans     &trans  &trans
            >;
        };

        Game_Layer {
            display-name = "game";
            bindings = <
&kp ESC         &kp N1     &kp N2        &kp N3    &kp N4        &kp N5                       &kp N6                        &kp N7         &kp N8   &kp N9     &kp N0   &kp MINUS
&kp TAB         &kp NUBS   &kp Q         &kp W     &kp E         &kp R                        &kp T                         &kp Y          &kp U    &kp I      &kp O    &kp P
&kp LEFT_SHIFT  &kp LSHFT  &kp A         &kp S     &kp D         &kp F                        &kp G                         &kp H          &kp J    &kp K      &kp L    &mt RIGHT_SHIFT APOS
&kp LCTRL       &kp LCTRL  &kp Z         &kp X     &kp C         &kp V      &trans    &trans  &hrm_momentary_layer L_ADJ B  &kp N          &kp M    &kp COMMA  &kp DOT  &kp MINUS
                           &kp LEFT_GUI  &kp LALT  &kp LEFT_ALT  &kp SPACE  &trans    &trans  &mo L_GAME                    &kp BACKSPACE  &kp DEL  &kp RALT
            >;

            sensor-bindings = <&inc_dec_kp C_VOL_UP C_VOL_DN>;
        };

        symbol_layer {
            display-name = "symbol";
            bindings = <
&mod_taptap_150 DE_DEGREE DE_CARET  &macro_de_quote_open                            &macro_de_quote_close             &macro_Guillemets_open                &macro_Guillemets_close  &macro_bullet                                        &macro_plusminus   &macro_mult              &macro_div                &macro_ellipsis   &macro_nbsp           &macro_nnbsp
&kp TAB                             &macro_single_backtick_grave                    &mod_tapBackticTrippe 0 DE_MINUS  &mod_taptap_150 DE_EURO DE_LESS_THAN  &kp DE_GREATER_THAN      &kp PERCENT                                          &macro_zirkumflex  &kp DE_LEFT_BRACE        &kp DE_RIGHT_BRACE        &kp DE_COLON      &kp DE_DOLLAR         &mt DE_GRAVE DE_ACUTE
&kp LSHFT                           &mod_taptap_150 DE_EXCLAMATION DE_SINGLE_QUOTE  &kp DE_ASTERISK                   &kp DE_SLASH                          &kp DE_EQUAL             &kp DE_AMPERSAND                                     &kp DE_POUND       &kp DE_LEFT_PARENTHESIS  &kp DE_RIGHT_PARENTHESIS  &kp DE_SEMICOLON  &kp DE_DOUBLE_QUOTES  &kp DE_BACKSLASH
&kp LEFT_CONTROL                    &kp DE_TILDE                                    &kp DE_PLUS                       &kp DE_LEFT_BRACKET                   &kp DE_RIGHT_BRACKET     &kp DE_PIPE                        &trans    &trans  &kp RA(DE_Q)       &kp DE_UNDERSCORE        &kp COMMA                 &kp DE_PERIOD     &kp DE_UNDERSCORE     &macro_arrow_right
                                                                                    &trans                            &trans                                &trans                   &hrm_momentary_layer L_NUM2 SPACE  &trans    &trans  &trans             &trans                   &trans                    &trans
            >;

            sensor-bindings = <&inc_dec_kp C_VOL_UP C_VOL_DN>;
        };

        Numpad_Layer {
            display-name = "numpad";
            bindings = <
&kp ESCAPE        &none                        &none                        &none                        &none                        &none                              &kp KP_NUMLOCK    &none            &kp KP_DIVIDE    &kp KP_MULTIPLY  &kp DE_GRAVE                      &kp DE_ACUTE
&kp TAB           &kp LC(LS(F15))              &kp LS(LC(F16))              &kp LS(LC(F17))              &kp LS(LC(F18))              &kp LS(LC(F19))                    &kp DE_COLON      &kp KP_NUMBER_7  &kp KP_NUMBER_8  &kp KP_NUMBER_9  &kp KP_MINUS                      &kp DE_HASH
&kp LSHFT         &mod_taptap_150 LS(F15) F15  &mod_taptap_150 LS(F16) F16  &mod_taptap_150 LS(F17) F17  &mod_taptap_150 LS(F18) F18  &kp F19                            &kp DE_SEMICOLON  &kp KP_NUMBER_4  &kp KP_NUMBER_5  &kp KP_NUMBER_6  &hrm_shift_r RIGHT_SHIFT KP_PLUS  &kp LC(DE_PLUS)
&kp LEFT_CONTROL  &kp LC(F15)                  &kp LC(F16)                  &kp LC(F17)                  &kp LC(F18)                  &kp LC(F19)      &trans    &trans  &kp KP_NUMBER_0   &kp KP_N1        &kp KP_NUMBER_2  &kp KP_NUMBER_3  &kp KP_EQUAL                      &kp LC(DE_MINUS)
                                               &trans                       &trans                       &trans                       &trans           &trans    &trans  &kp SPACE         &kp KP_N0        &kp COMMA        &kp PERIOD
            >;

            sensor-bindings = <&inc_dec_kp C_VOL_UP C_VOL_DN>;
        };

        Navigation_Layer {
            display-name = "navigation";

            // ------------------------------------------------------------------------------------------------------------
            // | BTCLR | BT1  | BT2  |  BT3  |  BT4  |  BT5 |                |      |      |       |      |       |       |
            // |       | INS  | PSCR | GUI   |       |      |                | PGUP |      |   ^   |      |       |       |
            // |       | ALT  | CTRL | SHIFT |       | CAPS |                | PGDN |   <- |   v   |  ->  |  DEL  | BKSPC |
            // |       | UNDO | CUT  | COPY  | PASTE |      |      |  |      |      |      |       |      |       |       |
            //                |      |       |       |      |      |  |      |      |      |       |      |

            bindings = <
&kp ESCAPE        &kp F1        &kp F2       &kp F3                                     &kp F4                                &kp F5                                                   &kp F6              &kp F7          &kp F8              &kp F9               &kp F10           &kp F11
&kp TAB           &kp LA(TAB)   &kp LG(TAB)  &mod_taptap_150 LG(LC(LEFT_ARROW)) LS(F1)  &mod_taptap_150 LC(LG(RIGHT)) LS(F2)  &mod_taaap LA(F4) LS(F4)                                 &kp HOME            &none           &macro_select_word  &kp END              &kp END           &kp F12
&kp LEFT_SHIFT    &kp LC(A)     &kp ESCAPE   &kp BACKSPACE                              &kp DEL                               &kp ENTER                                                &kp LEFT            &kp DOWN        &kp UP_ARROW        &kp RIGHT            &kp LS(ENTER)     &macro_unstick_mods
&kp LEFT_CONTROL  &kp LC(DE_Z)  &kp LC(X)    &kp LC(C)                                  &kp LC(V)                             &mod_taptap_150 LS(LC(V)) LG(V)  &trans       &trans     &kp LC(LEFT_ARROW)  &kp PAGE_DOWN   &kp PAGE_UP         &kp LC(RIGHT_ARROW)  &kp LC(DE_MINUS)  &kp LC(DE_PLUS)
                                &trans       &trans                                     &trans                                &trans                           &kp ENTER    &kp ENTER  &kp SPACE           &kp C_PREVIOUS  &kp C_PLAY_PAUSE    &kp C_NEXT
            >;

            sensor-bindings = <&inc_dec_kp C_VOL_UP C_VOL_DN>;
        };

        Adjust_Layer {
            // ----------------------------------------------------------------------------------------------------------------------------
            // | BTCLR  |  BT1    |  BT2    |   BT3   |   BT4   |   BT5   |                  |      |      |       |      |       |       |
            // | EXTPWR | RGB_HUD | RGB_HUI | RGB_SAD | RGB_SAI | RGB_EFF |                  |      |      |       |      |       |       |
            // |        | RGB_BRD | RGB_BRI |         |         |         |                  |      |      |       |      |       |       |
            // |        |         |         |         |         |         | RGB_TOG | |      |      |      |       |      |       |       |
            //                    |         |         |         |         |         | |      |      |      |       |      |

            display-name = "adjust";
            bindings = <
&bt BT_CLR        &bt BT_SEL 0     &bt BT_SEL 1         &bt BT_SEL 2         &bt BT_SEL 3         &bt BT_SEL 4                            &out OUT_USB  &out OUT_BLE  &bt BT_CLR    &bt BT_CLR_ALL  &none         &kp KP_NUMLOCK
&bt BT_CLR_ALL    &to L_BASE       &to L_CAPS           &to L_SIGG           &to L_GAME           &to L_NAV                               &bt BT_SEL 0  &bt BT_SEL 1  &bt BT_SEL 2  &bt BT_SEL 3    &bt BT_SEL 4  &kp LS(LA(LC(F12)))
&kp LA(CAPSLOCK)  &kp PRINTSCREEN  &kp LA(PRINTSCREEN)  &kp LS(PRINTSCREEN)  &kp LC(PRINTSCREEN)  &none                                   &kp LS(F14)   &kp LS(F14)   &kp F14       &kp LC(F15)     &none         &none
&bootloader       &sys_reset       &none                &aim AIM_ON          &aim AIM_OFF         &none             &trans        &trans  &none         &none         &none         &none           &sys_reset    &bootloader
                                   &none                &none                &kp C_PREV           &kp C_PLAY_PAUSE  &kp C_NEXT    &none   &none         &none         &none         &none
            >;

            sensor-bindings = <&inc_dec_kp C_VOLUME_UP C_VOL_DN>;
        };

        number_layer_duplicate {
            display-name = "number_duplicate";
            bindings = <
&kp ESCAPE        &none                                         &none                       &none                         &none                           &none                        &none                              &none                             &none                           &none                         &none                        &none
&kp TAB           &kp F1                                        &kp F2                      &kp F3                        &kp F4                          &kp F5                       &kp F6                             &kp F7                            &kp F8                          &kp F9                        &kp F10                      &kp F11
&kp LSHFT         &hrm_mods_left_short_tappingterm LEFT_GUI N1  &hrm_mods_left LEFT_ALT N2  &hrm_mods_left LEFT_SHIFT N3  &hrm_mods_left LEFT_CONTROL N4  &kp N5                       &kp N6                             &hrm_mods_right RIGHT_CONTROL N7  &hrm_mods_right RIGHT_SHIFT N8  &hrm_mods_right LALT N9       &hrm_mods_right LEFT_GUI N0  &kp F12
&kp LEFT_CONTROL  &kp DE_MINUS                                  &kp DE_PLUS                 &kp DE_ASTERISK               &kp DE_SLASH                    &kp N0  &trans    &trans     &none                              &mod_taptap_150 J SPACE           &mod_taptap_150 K COMMA         &mod_taptap_150 DE_COLON DOT  &kp DE_MINUS                 &kp DE_UNDERSCORE
                                                                &trans                      &trans                        &trans                          &trans  &trans    &kp ENTER  &hrm_momentary_layer L_SYMB SPACE  &trans                            &trans                          &trans
            >;

            sensor-bindings = <&inc_dec_kp C_VOL_UP C_VOL_DN>;
        };
    };
};
